# STM32WL55xx register map
File version: 1.0
Registers are 32-bit, read-write, reset 0x0 unless marked. A register's access mark holds for its fields unless they carry their own. Offsets are from the block's base; [hi:lo] are bit positions; {n}, {i} and the like mark numbered series.

## CRC — CRC calculation unit
Base 0x40023000
0x00 DR — CRC Data register
  [31:0] DR — Data register bits
0x04 IDR — CRC Independent data register
  [31:0] IDR — General-purpose 8-bits data register bits
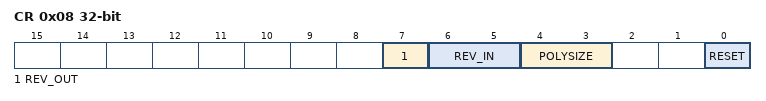
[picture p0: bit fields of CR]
0x08 CR — CRC Control register
  [7] REV_OUT — REV_OUT Reverse Output Data bits
    0=NONE (Output Data bit order not affected); 1=BIT (Output Data bit reversal done by bit)
  [6:5] REV_IN — REV_IN Reverse Input Data bits
    0=NONE (Input Data bit order not affected); 1=BYTE (Input Data bit reversal done by byte); 2=HALFWORD (Input Data bit reversal done by half-word); 3=WORD (Input Data bit reversal done by word)
  [4:3] POLYSIZE — Polynomial size bits
    0=POLYLENGTH_32B (32 bits Polynomial size); 1=POLYLENGTH_16B (16 bits Polynomial size); 2=POLYLENGTH_8B (8 bits Polynomial size); 3=POLYLENGTH_7B (7 bits Polynomial size)
  [0] RESET — RESET the CRC computation unit bit
0x10 INIT — Initial CRC value register
  [31:0] INIT — Initial CRC value bits
0x14 POL — CRC polynomial register
  [31:0] POL — Coefficients of the polynomial

## GPIOA — General Purpose I/O
Base 0x48000000
Same registers: GPIOB 0x48000400, GPIOC 0x48000800, GPIOH 0x48001C00
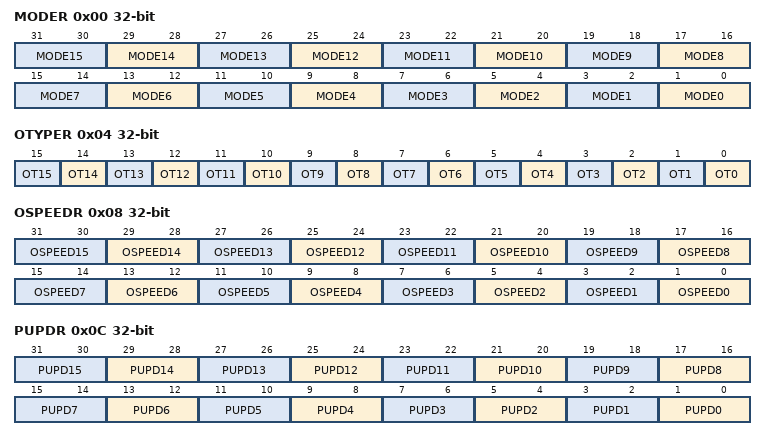
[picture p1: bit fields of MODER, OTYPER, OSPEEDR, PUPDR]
0x00 MODER — GPIO port mode register
  [2n+1:2n] MODE{n} (n=0..15)
0x04 OTYPER — GPIO port output type register
  [n] OT{n} (n=0..15)
0x08 OSPEEDR — GPIO port output speed register
  [2n+1:2n] OSPEED{n} (n=0..15)
0x0C PUPDR — GPIO port pull-up/pull-down register
  [2n+1:2n] PUPD{n} (n=0..15)
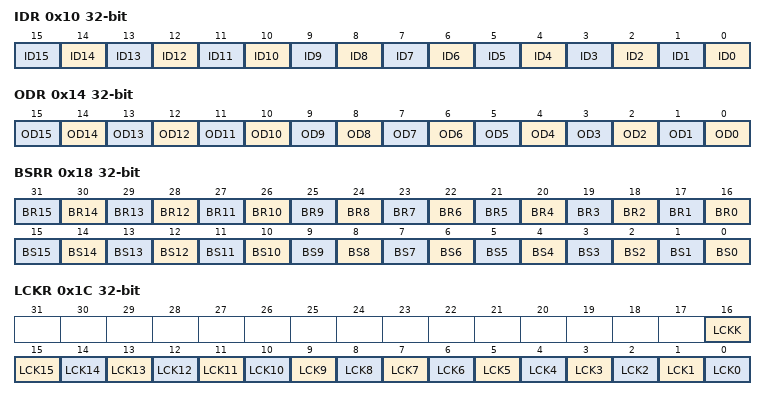
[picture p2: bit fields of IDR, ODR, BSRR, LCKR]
0x10 IDR — GPIO port input data register
  [n] ID{n} (n=0..15)
0x14 ODR — GPIO port output data register
  [n] OD{n} (n=0..15)
0x18 BSRR — GPIO port bit set/reset register
  [n+16] BR{n} (n=0..15), [n] BS{n} (n=0..15)
0x1C LCKR — GPIO port configuration lock register
  [16] LCKK, [n] LCK{n} (n=0..15)
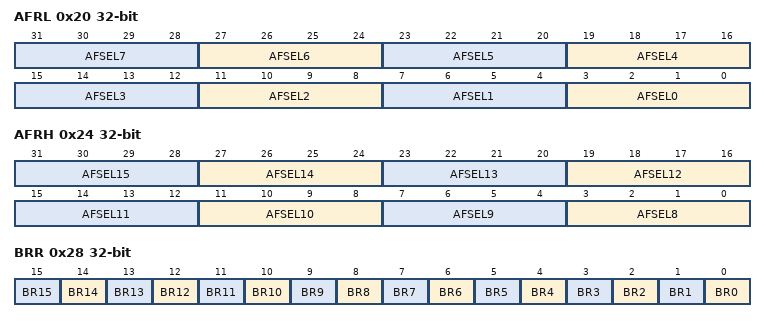
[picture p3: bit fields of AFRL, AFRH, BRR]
0x20 AFRL — GPIO alternate function registers
  [4n+3:4n] AFSEL{n} (n=0..7)
0x24 AFRH — GPIO alternate function registers
  [4n-29:4n-32] AFSEL{n} (n=8..15)
0x28 BRR — GPIO Bit Reset register
  [n] BR{n} (n=0..15)

## EXTI — Async Interrupts and Events Controller
Base 0x58000800
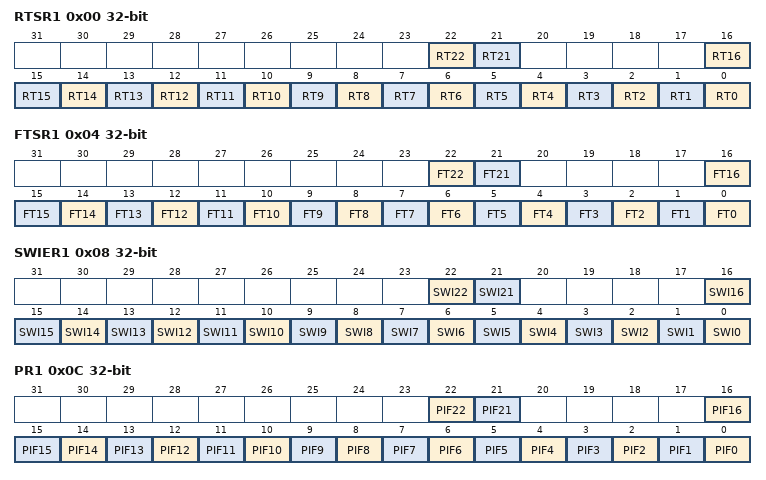
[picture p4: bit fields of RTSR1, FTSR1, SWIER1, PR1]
0x00 RTSR1 — EXTI rising trigger selection register [31:0]
  [22] RT22 — Rising trigger event configuration bit of line 22
  [21] RT21 — Rising trigger event configuration bit of line 21
  [n] RT{n} (n=0..16) — Rising trigger event configuration bit of line {n}
0x04 FTSR1 — EXTI falling trigger selection register [31:0]
  [22] FT22 — Falling trigger event configuration bit of line 22
  [21] FT21 — Falling trigger event configuration bit of line 21
  [n] FT{n} (n=0..16) — Falling trigger event configuration bit of line {n}
0x08 SWIER1 — EXTI software interrupt event register [31:0]
  [22] SWI22 — Software Interrupt on line 22
  [21] SWI21 — Software Interrupt on line 21
  [n] SWI{n} (n=0..16) — Software Interrupt on line {n}
0x0C PR1 — EXTI pending register [31:0]
  [22] PIF22 — Pending bit for line 22
  [21] PIF21 — Pending bit for line 21
  [n] PIF{n} (n=0..16) — Pending bit for line {n}
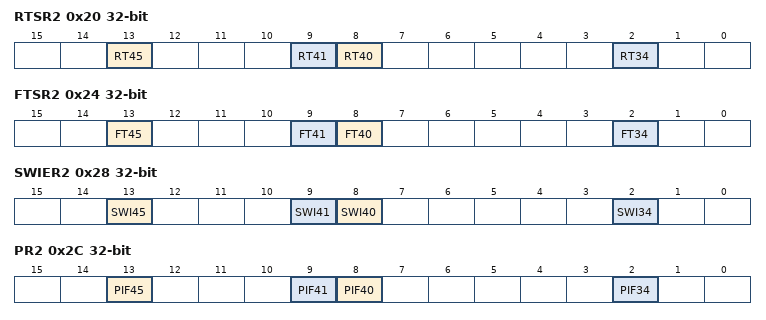
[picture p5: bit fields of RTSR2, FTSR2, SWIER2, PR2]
0x20 RTSR2 — EXTI rising trigger selection register [31:0]
  [13] RT45 — Rising trigger event configuration bit of line 45
  [9] RT41 — Rising trigger event configuration bit of line 41
  [8] RT40 — Rising trigger event configuration bit of line 40
  [2] RT34 — Rising trigger event configuration bit of line 34
0x24 FTSR2 — EXTI falling trigger selection register [31:0]
  [13] FT45 — Falling trigger event configuration bit of line 45
  [9] FT41 — Falling trigger event configuration bit of line 41
  [8] FT40 — Falling trigger event configuration bit of line 40
  [2] FT34 — Falling trigger event configuration bit of line 34
0x28 SWIER2 — EXTI software interrupt event register [31:0]
  [13] SWI45 — Software Interrupt on line 45
  [9] SWI41 — Software Interrupt on line 41
  [8] SWI40 — Software Interrupt on line 40
  [2] SWI34 — Software Interrupt on line 34
0x2C PR2 — EXTI pending register [31:0]
  [13] PIF45 — Pending bit for line 45
  [9] PIF41 — Pending bit for line 41
  [8] PIF40 — Pending bit for line 40
  [2] PIF34 — Pending bit for line 34
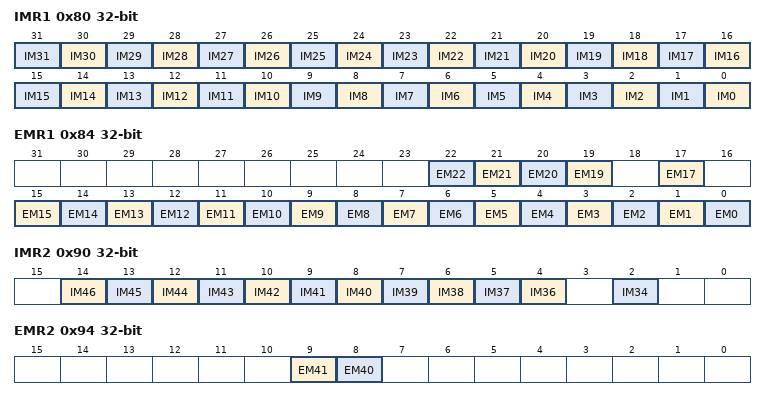
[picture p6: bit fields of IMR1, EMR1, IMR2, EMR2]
0x80 IMR1 — EXTI wakeup with interrupt mask register for cpu1 [31:0]
  [n] IM{n} (n=0..31) — CPU1 Interrupt Mask on line {n}
0x84 EMR1 — EXTI wakeup with event mask register for cpu1 [31:0]
  [n] EM{n} (n=19..22) — CPU1 Event Mask on line {n}
  [17] EM17 — CPU1 Event Mask on line 17
  [n] EM{n} (n=0..15) — CPU1 Event Mask on line {n}
0x90 IMR2 — EXTI wakeup with interrupt mask register for cpu1 [31:0]
  [n-32] IM{n} (n=36..46) — CPU1 Interrupt Mask on line {n}
  [2] IM34 — CPU1 Interrupt Mask on line 34
0x94 EMR2 — EXTI wakeup with event mask register for cpu1 [31:0]
  [9] EM41 — CPU1 Event Mask on line 41
  [8] EM40 — CPU1 Event Mask on line 40
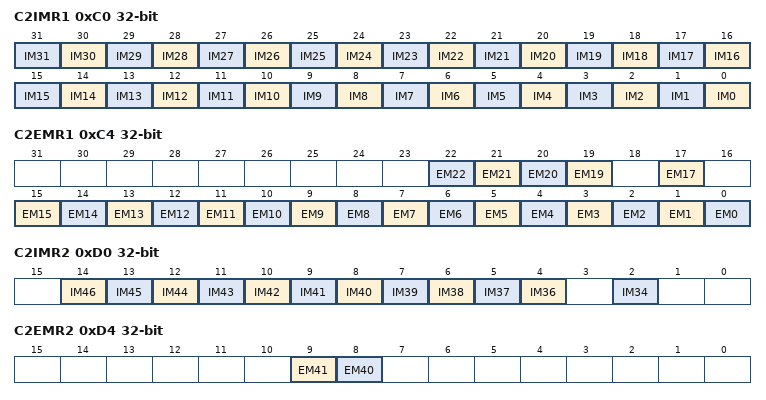
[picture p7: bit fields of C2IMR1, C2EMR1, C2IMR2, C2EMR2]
0xC0 C2IMR1 — EXTI wakeup with interrupt mask register for cpu2 [31:0]
  [n] IM{n} (n=0..31) — CPU2 Interrupt Mask on line {n}
0xC4 C2EMR1 — EXTI wakeup with event mask register for cpu2 [31:0]
  [n] EM{n} (n=19..22) — CPU2 Event Mask on line {n}
  [17] EM17 — CPU2 Event Mask on line 17
  [n] EM{n} (n=0..15) — CPU2 Event Mask on line {n}
0xD0 C2IMR2 — EXTI wakeup with interrupt mask register for cpu2 [31:0]
  [n-32] IM{n} (n=36..46) — CPU2 Interrupt Mask on line {n}
  [2] IM34 — CPU2 Interrupt Mask on line 34
0xD4 C2EMR2 — EXTI wakeup with event mask register for cpu2 [31:0]
  [9] EM41 — CPU2 Event Mask on line 41
  [8] EM40 — CPU2 Event Mask on line 40
